# max32665 register map
Vendor: Maxim-Integrated; Series: ARMCM3; File version: 1.0
CPU: CM4 r2p1, little endian, MPU, FPU, 3 interrupt priority bits
Registers are 32-bit, read-write, reset 0x0 unless marked. A register's access mark holds for its fields unless they carry their own. Offsets are from the block's base; [hi:lo] are bit positions; {n}, {i} and the like mark numbered series.

## PTG — Pulse Train Generation
Base 0x4003C000
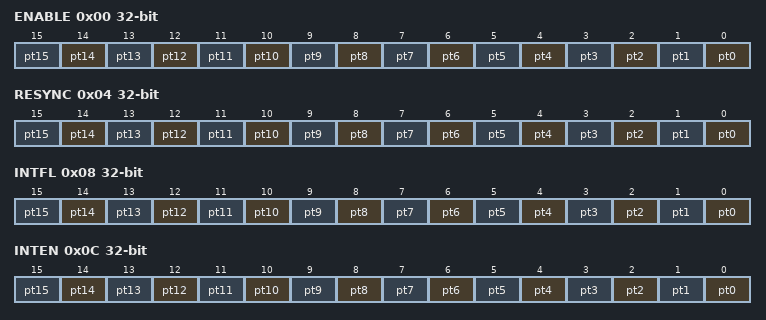
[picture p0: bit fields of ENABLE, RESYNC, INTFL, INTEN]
0x00 ENABLE — Global Enable/Disable Controls for All Pulse Trains
  [n] pt{n} (n=0..15) — Enable/Disable control for PT{n}
0x04 RESYNC — Global Resync (All Pulse Trains) Control
  [n] pt{n} (n=0..15) — Resync control for PT{n}
0x08 INTFL — Pulse Train Interrupt Flags
  [n] pt{n} (n=0..15) — Pulse Train {n} Stopped Interrupt Flag
0x0C INTEN — Pulse Train Interrupt Enable/Disable
  [n] pt{n} (n=0..15) — Pulse Train {n} Stopped Interrupt Enable/Disable
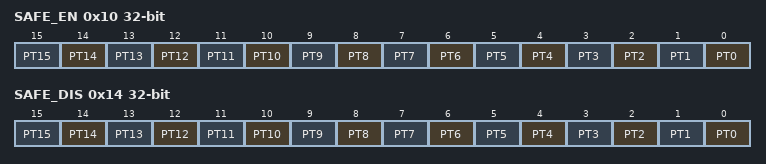
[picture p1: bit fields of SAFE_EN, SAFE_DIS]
0x10 SAFE_EN wo — Pulse Train Global Safe Enable.
  [n] PT{n} (n=0..15)
0x14 SAFE_DIS wo — Pulse Train Global Safe Disable.
  [n] PT{n} (n=0..15)

## PT — Pulse Train
Base 0x4003C020
Same registers: PT{n} {0x4003C020+0x20*n} (n=1..15)
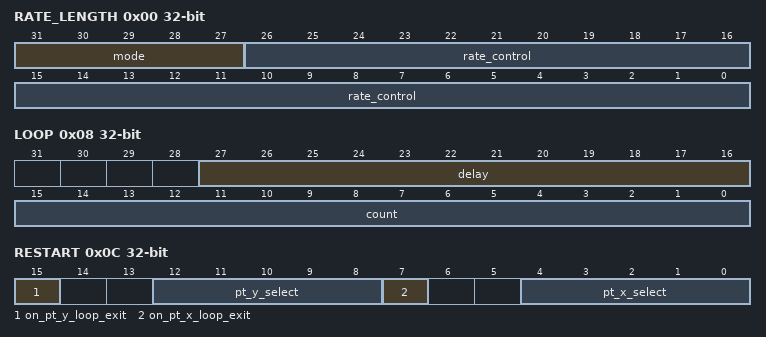
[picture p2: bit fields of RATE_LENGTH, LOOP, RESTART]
0x00 RATE_LENGTH — Pulse Train Configuration
  [31:27] mode — Pulse Train Output Mode/Train Length
    0=32_BIT (Pulse train, 32 bit pattern.); 1=SQUARE_WAVE (Square wave mode.); {v}={v}_BIT (Pulse train, {v} bit pattern.) (v=2..31)
  [26:0] rate_control — Pulse Train Enable and Rate Control. Set to 0 to disable the Pulse Train.
0x04 TRAIN — Write the repeating bit pattern that is shifted out, LSB first, when configured in Pulse Train mode. See PT_RATE_LENGTH.mode for setting the length.
0x08 LOOP — Pulse Train Loop Count
  [27:16] delay — Delay between loops of the Pulse Train in PT Peripheral Clock cycles
  [15:0] count — Number of loops for this pulse train to repeat.
0x0C RESTART — Pulse Train Auto-Restart Configuration.
  [15] on_pt_y_loop_exit — Enable Auto-Restart on PT Y Loop Exit
  [12:8] pt_y_select — Auto-Restart PT Y Select
  [7] on_pt_x_loop_exit — Enable Auto-Restart on PT X Loop Exit
  [4:0] pt_x_select — Auto-Restart PT X Select

## SDMA — Smart DMA
Base 0x40036000
0x00 IP ro — Q30E Instruction Pointer.
0x04 SP ro — Q30E Stack Pointer.
0x08 DP0 ro — Q30E Data Pointer 0.
0x0C DP1 ro — Q30E Data Pointer 1.
0x10 BP ro — Q30E Frame Pointer Base.
0x14 OFFS ro — Q30E Frame Pointer Offset.
0x18 LC0 ro — Q30E Loop Counter 0.
0x1C LC1 ro — Q30E Loop Counter 1.
{0x20+4i} A{i} ro (i=0..3) — Q30E Accumulator {i}.
0x30 WDCN ro — Q30E Watchdog Control.
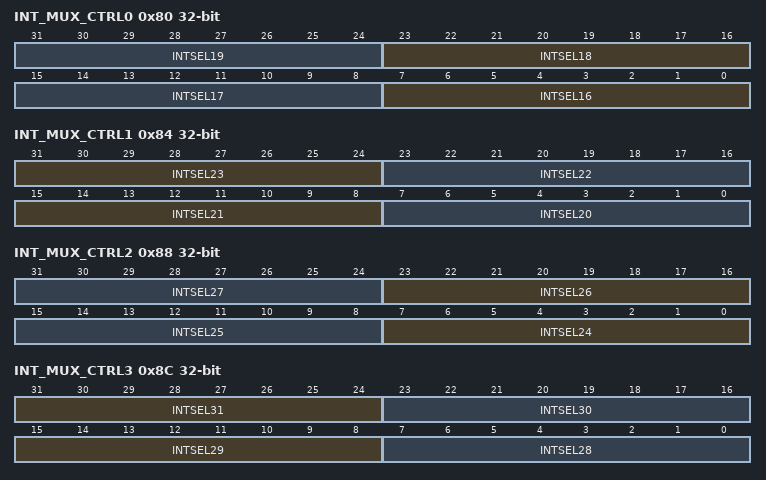
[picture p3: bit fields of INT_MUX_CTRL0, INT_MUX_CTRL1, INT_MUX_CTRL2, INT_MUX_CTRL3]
0x80 INT_MUX_CTRL0 — Interrupt Mux Control 0.
  [8n-121:8n-128] INTSEL{n} (n=16..19) — Interrupt Selection For {n}th Interrupt.
0x84 INT_MUX_CTRL1 — Interrupt Mux Control 1.
  [31:24] INTSEL23 — Interrupt Selection For 23rd Interrupt.
  [23:16] INTSEL22 — Interrupt Selection For 22nd Interrupt.
  [15:8] INTSEL21 — Interrupt Selection For 21st Interrupt.
  [7:0] INTSEL20 — Interrupt Selection For 20th Interrupt.
0x88 INT_MUX_CTRL2 — Interrupt Mux Control 2.
  [8n-185:8n-192] INTSEL{n} (n=24..27) — Interrupt Selection For {n}th Interrupt.
0x8C INT_MUX_CTRL3 — Interrupt Mux Control 3.
  [31:24] INTSEL31 — Interrupt Selection For 31st Interrupt.
  [23:16] INTSEL30 — Interrupt Selection For 30th Interrupt.
  [15:8] INTSEL29 — Interrupt Selection For 29th Interrupt.
  [7:0] INTSEL28 — Interrupt Selection For 28th Interrupt.
0x90 IP_ADDR — Configurable starting IP address for Q30E.
  [31:0] START_IP_ADDR — Starting IP address for Q30E
0x94 CTRL — Control Register.
  [0] EN — Enable SDMA.
    0=dis (Disable SDMA.); 1=en (Enable SDMA.)
0xA0 INT_IN_CTRL — Interrupt Input From CPU Control Register.
  [0] INTSET — Set Interrupt Flag.
    0=dis (Set interrupt Flag to 0.); 1=set (Set Interrupt Flag to 1.)
0xA4 INT_IN_FLAG — Interrupt Input From CPU Flag.
  [0] INTFLAG — Interrupt Flag.
    0=No Effect; 1=clear (INT_IN_FLAG =0)
0xA8 INT_IN_IE — Interrupt Input From CPU Enable.
  [0] INT_IN_EN — Interrupt Enable.
0xB0 IRQ_FLAG — Interrupt Output To CPU Flag.
  [0] IRQ_FLAG — Interrupt Flag.
0xB4 IRQ_IE — Interrupt Output To CPU Control Register.
  [0] IRQ_EN — Interrupt Enable.
